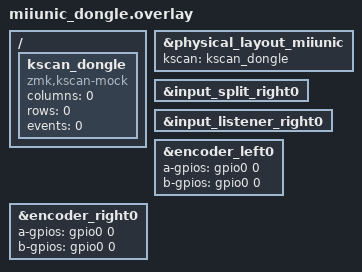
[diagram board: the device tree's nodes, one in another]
#include "miiunic.dtsi"

/ {
    kscan_dongle: kscan_dongle {
        compatible = "zmk,kscan-mock";
        columns = <0>;
        rows = <0>;
        events = <0>;
    };
};

&physical_layout_miiunic {
    kscan = <&kscan_dongle>;
};
// == Input devices ==
// Input devices on peripheral parts
// Enabling input listeners and input-split to receive input events from peripherals
&input_split_right0 { status = "okay"; };
&input_listener_right0 { status = "okay"; };

// Assigning dummy pins to other part's encoders
// just to satisfy the devicetree requirements.
// No code will be compiled for these disabled encoders.
&encoder_left0 {
    a-gpios = <&gpio0 0 (GPIO_ACTIVE_HIGH | GPIO_PULL_UP)>;
    b-gpios = <&gpio0 0 (GPIO_ACTIVE_HIGH | GPIO_PULL_UP)>;
};
&encoder_right0 {
    a-gpios = <&gpio0 0 (GPIO_ACTIVE_HIGH | GPIO_PULL_UP)>;
    b-gpios = <&gpio0 0 (GPIO_ACTIVE_HIGH | GPIO_PULL_UP)>;
};

